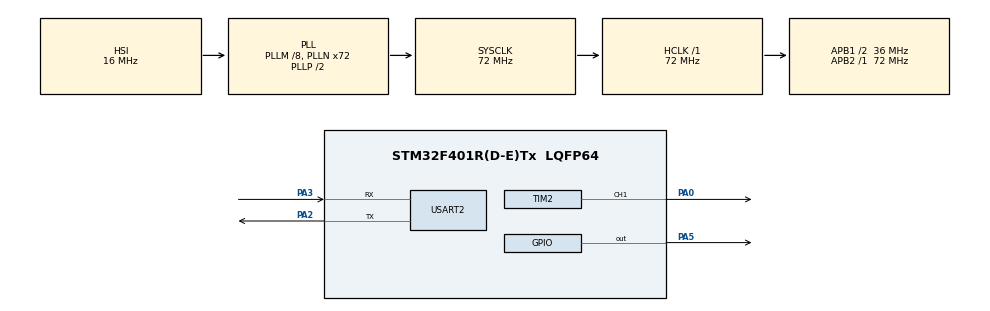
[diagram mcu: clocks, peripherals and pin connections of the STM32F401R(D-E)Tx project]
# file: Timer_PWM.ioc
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Mcu.Family=STM32F4
Mcu.Name=STM32F401R(D-E)Tx
Mcu.Package=LQFP64
NVIC.PriorityGroup=NVIC_PRIORITYGROUP_4
NVIC.TIM2_IRQn=true\:0\:0\:false\:false\:true\:true\:true
PA0-WKUP.Signal=S_TIM2_CH1_ETR
PA13.Mode=Serial_Wire
PA13.Signal=SYS_JTMS-SWDIO
PA14.Mode=Serial_Wire
PA14.Signal=SYS_JTCK-SWCLK
PA2.Mode=Asynchronous
PA2.Signal=USART2_TX
PA3.Mode=Asynchronous
PA3.Signal=USART2_RX
PA5.Signal=GPIO_Output
PH0\ -\ OSC_IN.Mode=HSE-External-Clock-Source
PH0\ -\ OSC_IN.Signal=RCC_OSC_IN
PH1\ -\ OSC_OUT.Mode=HSE-External-Clock-Source
PH1\ -\ OSC_OUT.Signal=RCC_OSC_OUT
ProjectManager.HeapSize=0x200
ProjectManager.StackSize=0x400
ProjectManager.TargetToolchain=STM32CubeIDE
RCC.48MHZClocksFreq_Value=36000000
RCC.AHBFreq_Value=72000000
RCC.APB1CLKDivider=RCC_HCLK_DIV2
RCC.APB1Freq_Value=36000000
RCC.APB1TimFreq_Value=72000000
RCC.APB2Freq_Value=72000000
RCC.APB2TimFreq_Value=72000000
RCC.CortexFreq_Value=72000000
RCC.HCLKFreq_Value=72000000
RCC.HSE_VALUE=8000000
RCC.HSI_VALUE=16000000
RCC.LSE_VALUE=32768
RCC.PLLM=8
RCC.PLLN=72
RCC.SYSCLKFreq_VALUE=72000000
RCC.SYSCLKSource=RCC_SYSCLKSOURCE_PLLCLK
RCC.VCOOutputFreq_Value=144000000
SH.S_TIM2_CH1_ETR.0=TIM2_CH1,PWM Generation1 CH1
TIM2.Channel-PWM\ Generation1\ CH1=TIM_CHANNEL_1
USART2.VirtualMode=VM_ASYNC
board=custom

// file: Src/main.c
/* USER CODE BEGIN Header */
/**
  ******************************************************************************
  * @file           : main.c
  * @brief          : Main program body
  ******************************************************************************
  * @attention
  *
  * <h2><center>&copy; Copyright (c) 2021 STMicroelectronics.
  * All rights reserved.</center></h2>
  *
  * This software component is licensed by ST under BSD 3-Clause license,
  * the "License"; You may not use this file except in compliance with the
  * License. You may obtain a copy of the License at:
  *                        opensource.org/licenses/BSD-3-Clause
  *
  ******************************************************************************
  */
/* USER CODE END Header */
#include "main.h"

TIM_HandleTypeDef htim2;

UART_HandleTypeDef huart2;

void SystemClock_Config(void);
static void MX_GPIO_Init(void);
static void MX_TIM2_Init(void);
static void MX_USART2_UART_Init(void);

int main(void)
{

  /* MCU Configuration--------------------------------------------------------*/

  /* Reset of all peripherals, Initializes the Flash interface and the Systick. */
  HAL_Init();

  /* Configure the system clock */
  SystemClock_Config();

  /* Initialize all configured peripherals */
  MX_GPIO_Init();
  MX_TIM2_Init();
  MX_USART2_UART_Init();
  /* USER CODE BEGIN 2 */

   HAL_TIM_PWM_Start_IT(&htim2, TIM_CHANNEL_1);

   HAL_TIM_PWM_Start_IT(&htim2, TIM_CHANNEL_2);

   HAL_TIM_PWM_Start_IT(&htim2, TIM_CHANNEL_3);

  /* USER CODE END 2 */

  /* Infinite loop */
  while (1)
  {

  }
}

 void HAL_TIM_PWM_PulseFinishedCallback(TIM_HandleTypeDef *htim)
{

}

void SystemClock_Config(void)
{
  RCC_OscInitTypeDef RCC_OscInitStruct = {0};
  RCC_ClkInitTypeDef RCC_ClkInitStruct = {0};

  /** Configure the main internal regulator output voltage
  */
  __HAL_RCC_PWR_CLK_ENABLE();
  __HAL_PWR_VOLTAGESCALING_CONFIG(PWR_REGULATOR_VOLTAGE_SCALE2);
  /** Initializes the RCC Oscillators according to the specified parameters
  * in the RCC_OscInitTypeDef structure.
  */
  RCC_OscInitStruct.OscillatorType = RCC_OSCILLATORTYPE_HSI;
  RCC_OscInitStruct.HSIState = RCC_HSI_ON;
  RCC_OscInitStruct.HSICalibrationValue = RCC_HSICALIBRATION_DEFAULT;
  RCC_OscInitStruct.PLL.PLLState = RCC_PLL_ON;
  RCC_OscInitStruct.PLL.PLLSource = RCC_PLLSOURCE_HSI;
  RCC_OscInitStruct.PLL.PLLM = 8;
  RCC_OscInitStruct.PLL.PLLN = 72;
  RCC_OscInitStruct.PLL.PLLP = RCC_PLLP_DIV2;
  RCC_OscInitStruct.PLL.PLLQ = 4;
  if (HAL_RCC_OscConfig(&RCC_OscInitStruct) != HAL_OK)
  {
    Error_Handler();
  }
  /** Initializes the CPU, AHB and APB buses clocks
  */
  RCC_ClkInitStruct.ClockType = RCC_CLOCKTYPE_HCLK|RCC_CLOCKTYPE_SYSCLK
                              |RCC_CLOCKTYPE_PCLK1|RCC_CLOCKTYPE_PCLK2;
  RCC_ClkInitStruct.SYSCLKSource = RCC_SYSCLKSOURCE_PLLCLK;
  RCC_ClkInitStruct.AHBCLKDivider = RCC_SYSCLK_DIV1;
  RCC_ClkInitStruct.APB1CLKDivider = RCC_HCLK_DIV2;
  RCC_ClkInitStruct.APB2CLKDivider = RCC_HCLK_DIV1;

  if (HAL_RCC_ClockConfig(&RCC_ClkInitStruct, FLASH_LATENCY_2) != HAL_OK)
  {
    Error_Handler();
  }
}

static void MX_TIM2_Init(void)
{

  TIM_MasterConfigTypeDef sMasterConfig = {0};
  TIM_OC_InitTypeDef sConfigOC = {0};

  htim2.Instance = TIM2;
  htim2.Init.Prescaler = 72-1;
  htim2.Init.CounterMode = TIM_COUNTERMODE_UP;
  htim2.Init.Period = 76923076;
  htim2.Init.ClockDivision = TIM_CLOCKDIVISION_DIV1;
  htim2.Init.AutoReloadPreload = TIM_AUTORELOAD_PRELOAD_DISABLE;
  if (HAL_TIM_PWM_Init(&htim2) != HAL_OK)
  {
    Error_Handler();
  }
  sMasterConfig.MasterOutputTrigger = TIM_TRGO_RESET;
  sMasterConfig.MasterSlaveMode = TIM_MASTERSLAVEMODE_DISABLE;
  if (HAL_TIMEx_MasterConfigSynchronization(&htim2, &sMasterConfig) != HAL_OK)
  {
    Error_Handler();
  }
  sConfigOC.OCMode = TIM_OCMODE_PWM1;

  sConfigOC.OCPolarity = TIM_OCPOLARITY_HIGH;
  sConfigOC.OCFastMode = TIM_OCFAST_DISABLE;

  sConfigOC.Pulse =( htim2.Init.Period*20)/100;
  if (HAL_TIM_PWM_ConfigChannel(&htim2, &sConfigOC, TIM_CHANNEL_1) != HAL_OK)
  {
    Error_Handler();
  }

  sConfigOC.Pulse =( htim2.Init.Period*40)/100;
  if (HAL_TIM_PWM_ConfigChannel(&htim2, &sConfigOC, TIM_CHANNEL_1) != HAL_OK)
  {
    Error_Handler();
  }

  sConfigOC.Pulse =( htim2.Init.Period*60)/100;
  if (HAL_TIM_PWM_ConfigChannel(&htim2, &sConfigOC, TIM_CHANNEL_1) != HAL_OK)
  {
    Error_Handler();
  }
  HAL_TIM_MspPostInit(&htim2);

}

static void MX_USART2_UART_Init(void)
{

  huart2.Instance = USART2;
  huart2.Init.BaudRate = 115200;
  huart2.Init.WordLength = UART_WORDLENGTH_8B;
  huart2.Init.StopBits = UART_STOPBITS_1;
  huart2.Init.Parity = UART_PARITY_NONE;
  huart2.Init.Mode = UART_MODE_TX_RX;
  huart2.Init.HwFlowCtl = UART_HWCONTROL_NONE;
  huart2.Init.OverSampling = UART_OVERSAMPLING_16;
  if (HAL_UART_Init(&huart2) != HAL_OK)
  {
    Error_Handler();
  }

}

static void MX_GPIO_Init(void)
{
  GPIO_InitTypeDef GPIO_InitStruct = {0};

  /* GPIO Ports Clock Enable */
  __HAL_RCC_GPIOH_CLK_ENABLE();
  __HAL_RCC_GPIOA_CLK_ENABLE();

  /*Configure GPIO pin Output Level */
  HAL_GPIO_WritePin(GPIOA, GPIO_PIN_5, GPIO_PIN_RESET);

  /*Configure GPIO pin : PA5 */
  GPIO_InitStruct.Pin = GPIO_PIN_5;
  GPIO_InitStruct.Mode = GPIO_MODE_OUTPUT_PP;
  GPIO_InitStruct.Pull = GPIO_NOPULL;
  GPIO_InitStruct.Speed = GPIO_SPEED_FREQ_LOW;
  HAL_GPIO_Init(GPIOA, &GPIO_InitStruct);

}

void Error_Handler(void)
{
  __disable_irq();
  while (1)
  {
  }
}

/************************ (C) COPYRIGHT STMicroelectronics *****END OF FILE****/
